AUTOSAR XML (schema 4-2-2)
package /Components
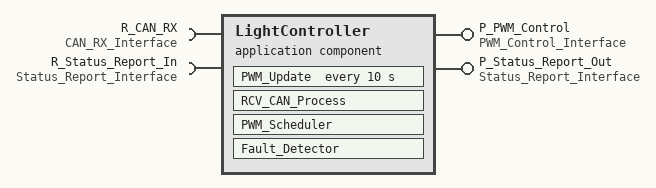
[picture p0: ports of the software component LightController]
  application sw component type LightController
    provide port P_PWM_Control: provided-interface=PWM_Control_Interface
    provide port P_Status_Report_Out: provided-interface=Status_Report_Interface
    require port R_CAN_RX: required-interface=CAN_RX_Interface
    require port R_Status_Report_In: required-interface=Status_Report_Interface
    behavior LightController_Behavior
      background event Fault_Monitor_Event: start-on-event=HW_Monitor
      data received event CAN_Command_Received_Event: start-on-event=CAN_Rx_Handler
      init event Init_Event: start-on-event=CAN_Tx_Service
      timing event PWM_Update_Timing_Event: start-on-event=PWM_Update, period=10
      runnable RCV_CAN_Process: symbol=LightController_RCV_CAN_Process
        data-receive-point-by-arguments:
          access CAN_RX_Access: accessed-variable=R_CAN_RX.CAN_Frame
        data-receive-point-by-values:
          access CAN_RX_Value: accessed-variable=R_CAN_RX.Parsed_CAN_Signals
        data-send-points:
          access PWM_Command_Send: accessed-variable=P_PWM_Control.PWM_Channel_Command
      runnable PWM_Scheduler: minimum-start-interval=10, symbol=LightController_PWM_Scheduler
        data-receive-point-by-arguments:
          access Scheduler_Input_Access: accessed-variable=P_PWM_Control.PWM_Scheduler_Input
        data-receive-point-by-values:
          access Scheduler_State_Value: accessed-variable=P_PWM_Control.PWM_Scheduler_State
        data-send-points:
          access Scheduler_PWM_Send: accessed-variable=P_PWM_Control.PWM_Channel_Command
      runnable Fault_Detector: minimum-start-interval=100, symbol=LightController_Fault_Detector
        data-receive-point-by-arguments:
          access Status_Feedback_Arg: accessed-variable=R_Status_Report_In.Status_Report
        data-receive-point-by-values:
          access Status_Feedback_Value: accessed-variable=R_Status_Report_In.Status_Report
        data-send-points:
          access Status_Report_Send: accessed-variable=P_Status_Report_Out.Status_Report
